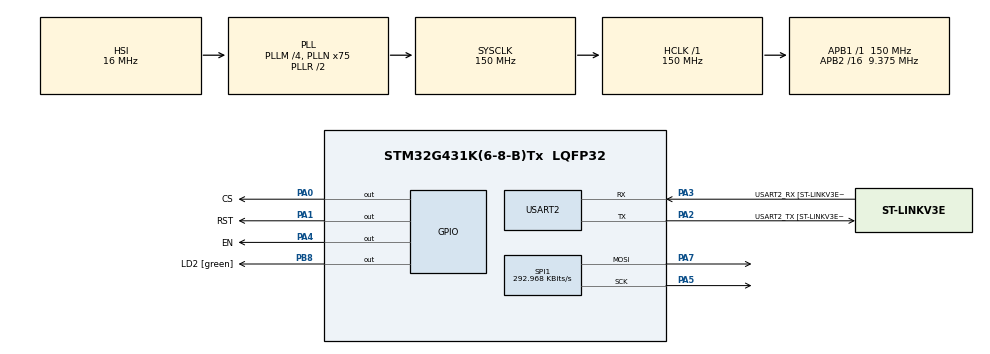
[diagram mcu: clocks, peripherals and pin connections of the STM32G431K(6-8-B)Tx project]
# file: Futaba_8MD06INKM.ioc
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Mcu.Family=STM32G4
Mcu.Name=STM32G431K(6-8-B)Tx
Mcu.Package=LQFP32
NVIC.PriorityGroup=NVIC_PRIORITYGROUP_4
PA0.GPIO_Label=CS
PA0.Signal=GPIO_Output
PA1.GPIO_Label=RST
PA1.Signal=GPIO_Output
PA13.GPIO_Label=T_SWDIO
PA13.Mode=Trace_Asynchronous_SW
PA13.Signal=SYS_JTMS-SWDIO
PA14.GPIO_Label=T_SWCLK
PA14.Mode=Trace_Asynchronous_SW
PA14.Signal=SYS_JTCK-SWCLK
PA2.GPIO_Label=USART2_TX [ST-LINKV3E_VCP_RX]
PA2.Mode=Asynchronous
PA2.Signal=USART2_TX
PA3.GPIO_Label=USART2_RX [ST-LINKV3E_VCP_TX]
PA3.Mode=Asynchronous
PA3.Signal=USART2_RX
PA4.GPIO_Label=EN
PA4.Signal=GPIO_Output
PA5.Mode=TX_Only_Simplex_Unidirect_Master
PA5.Signal=SPI1_SCK
PA7.Mode=TX_Only_Simplex_Unidirect_Master
PA7.Signal=SPI1_MOSI
PB3.GPIO_Label=T_SWO
PB3.Mode=Trace_Asynchronous_SW
PB3.Signal=SYS_JTDO-SWO
PB8-BOOT0.GPIO_Label=LD2 [green]
PB8-BOOT0.Signal=GPIO_Output
ProjectManager.HeapSize=0x200
ProjectManager.StackSize=0x400
ProjectManager.TargetToolchain=STM32CubeIDE
RCC.ADC12Freq_Value=150000000
RCC.AHBFreq_Value=150000000
RCC.APB1Freq_Value=150000000
RCC.APB1TimFreq_Value=150000000
RCC.APB2CLKDivider=RCC_HCLK_DIV16
RCC.APB2Freq_Value=9375000
RCC.APB2TimFreq_Value=18750000
RCC.CortexFreq_Value=150000000
RCC.EXTERNAL_CLOCK_VALUE=12288000
RCC.HCLKFreq_Value=150000000
RCC.HSE_VALUE=8000000
RCC.HSI48_VALUE=48000000
RCC.HSI_VALUE=16000000
RCC.LSE_VALUE=32768
RCC.PLLM=RCC_PLLM_DIV4
RCC.PLLN=75
RCC.SYSCLKFreq_VALUE=150000000
RCC.SYSCLKSource=RCC_SYSCLKSOURCE_PLLCLK
RCC.USBFreq_Value=150000000
RCC.VCOOutputFreq_Value=300000000
SPI1.BaudRatePrescaler=SPI_BAUDRATEPRESCALER_32
SPI1.CLKPhase=SPI_PHASE_2EDGE
SPI1.CLKPolarity=SPI_POLARITY_HIGH
SPI1.CalculateBaudRate=292.968 KBits/s
SPI1.DataSize=SPI_DATASIZE_8BIT
SPI1.Direction=SPI_DIRECTION_2LINES
SPI1.FirstBit=SPI_FIRSTBIT_LSB
SPI1.Mode=SPI_MODE_MASTER
SPI1.VirtualType=VM_MASTER
USART2.VirtualMode-Asynchronous=VM_ASYNC
USART2.WordLength=WORDLENGTH_8B
board=NUCLEO-G431KB

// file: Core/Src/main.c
/* USER CODE BEGIN Header */
/**
 ******************************************************************************
 * @file           	: main.c
 * @brief          	: Main program body
 *
 * Created on		: Feb 16, 2023
 * Author			: Michael
 * E-Mail			: michael.adam4@proton.me
 ******************************************************************************
 * @attention
 *
 * Copyright (c) 2023 STMicroelectronics.
 * All rights reserved.
 *
 * This software is licensed under terms that can be found in the LICENSE file
 * in the root directory of this software component.
 * If no LICENSE file comes with this software, it is provided AS-IS.
 *
 ******************************************************************************
 */
/* USER CODE END Header */
#include "main.h"

/* USER CODE BEGIN Includes */
#include "Futaba_8MD06INKM.h"

/* USER CODE END Includes */

SPI_HandleTypeDef hspi1;

UART_HandleTypeDef huart2;

void SystemClock_Config(void);
static void MX_GPIO_Init(void);
static void MX_USART2_UART_Init(void);
static void MX_SPI1_Init(void);

int main(void)
{

	/* MCU Configuration--------------------------------------------------------*/

	/* Reset of all peripherals, Initializes the Flash interface and the Systick. */
	HAL_Init();

	/* Configure the system clock */
	SystemClock_Config();

	/* Initialize all configured peripherals */
	MX_GPIO_Init();
	MX_USART2_UART_Init();
	MX_SPI1_Init();
	/* USER CODE BEGIN 2 */
	uint8_t buff[10];
	VFD_init();
	/* USER CODE END 2 */

	/* Infinite loop */
	while (1)
	{

		/* USER CODE BEGIN 3 */
		//VFD_Write_Str(1, "123456");

		for (uint8_t i = 0; i < 250; i += 10)
		{
			VFD_Brightness(i);
			sprintf(buff, "%d", i);
			VFD_Write_Str(1, buff);
			HAL_Delay(200);
		}

		HAL_Delay(2000);
		VFD_Clear();
	}
	/* USER CODE END 3 */
}

void SystemClock_Config(void)
{
	RCC_OscInitTypeDef RCC_OscInitStruct =
	{ 0 };
	RCC_ClkInitTypeDef RCC_ClkInitStruct =
	{ 0 };

	/** Configure the main internal regulator output voltage
	 */
	HAL_PWREx_ControlVoltageScaling(PWR_REGULATOR_VOLTAGE_SCALE1);

	/** Initializes the RCC Oscillators according to the specified parameters
	 * in the RCC_OscInitTypeDef structure.
	 */
	RCC_OscInitStruct.OscillatorType = RCC_OSCILLATORTYPE_HSI;
	RCC_OscInitStruct.HSIState = RCC_HSI_ON;
	RCC_OscInitStruct.HSICalibrationValue = RCC_HSICALIBRATION_DEFAULT;
	RCC_OscInitStruct.PLL.PLLState = RCC_PLL_ON;
	RCC_OscInitStruct.PLL.PLLSource = RCC_PLLSOURCE_HSI;
	RCC_OscInitStruct.PLL.PLLM = RCC_PLLM_DIV4;
	RCC_OscInitStruct.PLL.PLLN = 75;
	RCC_OscInitStruct.PLL.PLLP = RCC_PLLP_DIV2;
	RCC_OscInitStruct.PLL.PLLQ = RCC_PLLQ_DIV2;
	RCC_OscInitStruct.PLL.PLLR = RCC_PLLR_DIV2;
	if (HAL_RCC_OscConfig(&RCC_OscInitStruct) != HAL_OK)
	{
		Error_Handler();
	}

	/** Initializes the CPU, AHB and APB buses clocks
	 */
	RCC_ClkInitStruct.ClockType = RCC_CLOCKTYPE_HCLK | RCC_CLOCKTYPE_SYSCLK | RCC_CLOCKTYPE_PCLK1 | RCC_CLOCKTYPE_PCLK2;
	RCC_ClkInitStruct.SYSCLKSource = RCC_SYSCLKSOURCE_PLLCLK;
	RCC_ClkInitStruct.AHBCLKDivider = RCC_SYSCLK_DIV1;
	RCC_ClkInitStruct.APB1CLKDivider = RCC_HCLK_DIV1;
	RCC_ClkInitStruct.APB2CLKDivider = RCC_HCLK_DIV16;

	if (HAL_RCC_ClockConfig(&RCC_ClkInitStruct, FLASH_LATENCY_4) != HAL_OK)
	{
		Error_Handler();
	}
}

static void MX_SPI1_Init(void)
{

	/* SPI1 parameter configuration*/
	hspi1.Instance = SPI1;
	hspi1.Init.Mode = SPI_MODE_MASTER;
	hspi1.Init.Direction = SPI_DIRECTION_2LINES;
	hspi1.Init.DataSize = SPI_DATASIZE_8BIT;
	hspi1.Init.CLKPolarity = SPI_POLARITY_HIGH;
	hspi1.Init.CLKPhase = SPI_PHASE_2EDGE;
	hspi1.Init.NSS = SPI_NSS_SOFT;
	hspi1.Init.BaudRatePrescaler = SPI_BAUDRATEPRESCALER_32;
	hspi1.Init.FirstBit = SPI_FIRSTBIT_LSB;
	hspi1.Init.TIMode = SPI_TIMODE_DISABLE;
	hspi1.Init.CRCCalculation = SPI_CRCCALCULATION_DISABLE;
	hspi1.Init.CRCPolynomial = 7;
	hspi1.Init.CRCLength = SPI_CRC_LENGTH_DATASIZE;
	hspi1.Init.NSSPMode = SPI_NSS_PULSE_DISABLE;
	if (HAL_SPI_Init(&hspi1) != HAL_OK)
	{
		Error_Handler();
	}

}

static void MX_USART2_UART_Init(void)
{

	huart2.Instance = USART2;
	huart2.Init.BaudRate = 115200;
	huart2.Init.WordLength = UART_WORDLENGTH_8B;
	huart2.Init.StopBits = UART_STOPBITS_1;
	huart2.Init.Parity = UART_PARITY_NONE;
	huart2.Init.Mode = UART_MODE_TX_RX;
	huart2.Init.HwFlowCtl = UART_HWCONTROL_NONE;
	huart2.Init.OverSampling = UART_OVERSAMPLING_16;
	huart2.Init.OneBitSampling = UART_ONE_BIT_SAMPLE_DISABLE;
	huart2.Init.ClockPrescaler = UART_PRESCALER_DIV1;
	huart2.AdvancedInit.AdvFeatureInit = UART_ADVFEATURE_NO_INIT;
	if (HAL_UART_Init(&huart2) != HAL_OK)
	{
		Error_Handler();
	}
	if (HAL_UARTEx_SetTxFifoThreshold(&huart2, UART_TXFIFO_THRESHOLD_1_8) != HAL_OK)
	{
		Error_Handler();
	}
	if (HAL_UARTEx_SetRxFifoThreshold(&huart2, UART_RXFIFO_THRESHOLD_1_8) != HAL_OK)
	{
		Error_Handler();
	}
	if (HAL_UARTEx_DisableFifoMode(&huart2) != HAL_OK)
	{
		Error_Handler();
	}

}

static void MX_GPIO_Init(void)
{
	GPIO_InitTypeDef GPIO_InitStruct =
	{ 0 };

	/* GPIO Ports Clock Enable */
	__HAL_RCC_GPIOA_CLK_ENABLE();
	__HAL_RCC_GPIOB_CLK_ENABLE();

	/*Configure GPIO pin Output Level */
	HAL_GPIO_WritePin(GPIOA, CS_Pin | RST_Pin | EN_Pin, GPIO_PIN_RESET);

	/*Configure GPIO pin Output Level */
	HAL_GPIO_WritePin(LD2_GPIO_Port, LD2_Pin, GPIO_PIN_RESET);

	/*Configure GPIO pins : CS_Pin RST_Pin EN_Pin */
	GPIO_InitStruct.Pin = CS_Pin | RST_Pin | EN_Pin;
	GPIO_InitStruct.Mode = GPIO_MODE_OUTPUT_PP;
	GPIO_InitStruct.Pull = GPIO_NOPULL;
	GPIO_InitStruct.Speed = GPIO_SPEED_FREQ_LOW;
	HAL_GPIO_Init(GPIOA, &GPIO_InitStruct);

	/*Configure GPIO pin : LD2_Pin */
	GPIO_InitStruct.Pin = LD2_Pin;
	GPIO_InitStruct.Mode = GPIO_MODE_OUTPUT_PP;
	GPIO_InitStruct.Pull = GPIO_NOPULL;
	GPIO_InitStruct.Speed = GPIO_SPEED_FREQ_LOW;
	HAL_GPIO_Init(LD2_GPIO_Port, &GPIO_InitStruct);

}

void Error_Handler(void)
{
	__disable_irq();
	while (1)
	{
	}
}
